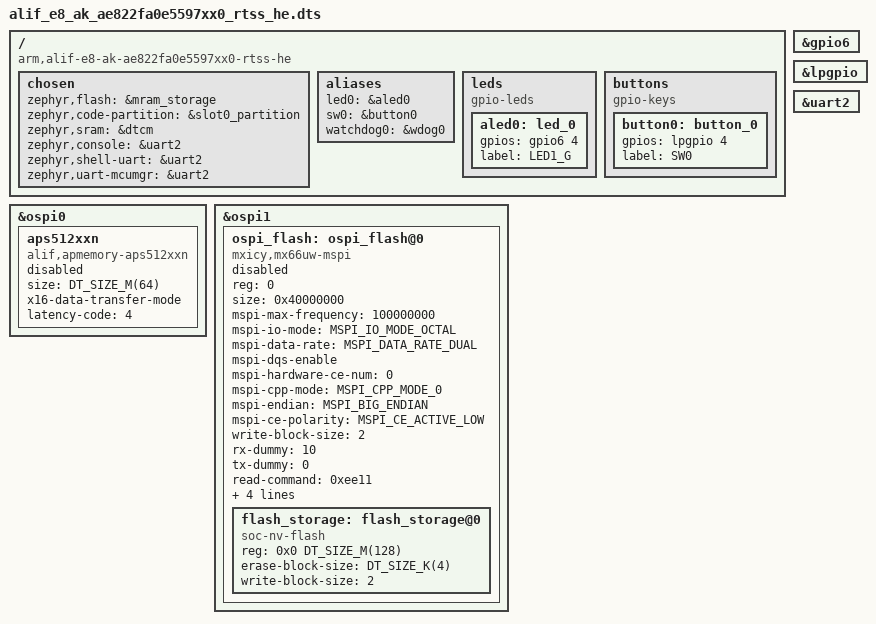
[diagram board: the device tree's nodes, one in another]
/* Copyright (c) 2025 Alif Semiconductor
 *
 * SPDX-License-Identifier: Apache-2.0
 */

/dts-v1/;

#include <alif/ensemble/common/e8_appkit.dtsi>
#include <alif/ensemble/common/ensemble_rtss_he.dtsi>
#include "../common/ensemble-e8-appkit-pinctrl.dtsi"
#include "../common/alif-sd-vsel.dtsi"

/ {
	compatible = "arm,alif-e8-ak-ae822fa0e5597xx0-rtss-he";
	#address-cells = <1>;
	#size-cells = <1>;

	chosen {
		zephyr,flash = &mram_storage;
		zephyr,code-partition = &slot0_partition;
		zephyr,sram = &dtcm;
		zephyr,console = &uart2;
		zephyr,shell-uart = &uart2;
		zephyr,uart-mcumgr = &uart2;
	};

	aliases {
		led0 = &aled0;
		sw0 = &button0;
		watchdog0 = &wdog0;
	};

	leds {
		compatible = "gpio-leds";
		aled0: led_0 {
			gpios = <&gpio6 4 0>;
			label = "LED1_G";
		};
	};
	buttons {
		compatible = "gpio-keys";
		button0: button_0 {
			gpios = <&lpgpio 4 0>;
			label = "SW0";
		};
	};
};

&gpio6 {
	status = "okay";
};

&lpgpio {
	status = "okay";
};

&uart2 {
	status = "okay";
};

&ospi0 {
	aps512xxn: aps512xxn {
		compatible = "alif,apmemory-aps512xxn";
		size = <DT_SIZE_M(64)>;
		x16-data-transfer-mode;
		latency-code = <4>;
		status = "disabled";
	};
};

&ospi1 {
	/* External Flash on MSPI */
	ospi_flash: ospi_flash@0 {
		compatible = "mxicy,mx66uw-mspi";
		reg = <0>;
		size = <0x40000000>;
		mspi-max-frequency = <100000000>;
		mspi-io-mode = "MSPI_IO_MODE_OCTAL";
		mspi-data-rate = "MSPI_DATA_RATE_DUAL";
		mspi-dqs-enable;
		mspi-hardware-ce-num = <0>;
		mspi-cpp-mode = "MSPI_CPP_MODE_0";
		mspi-endian = "MSPI_BIG_ENDIAN";
		mspi-ce-polarity = "MSPI_CE_ACTIVE_LOW";
		write-block-size = <2>;
		rx-dummy = <10>;
		tx-dummy = <0>;
		read-command = <0xee11>;
		write-command = <0x12ed>;
		command-length = "INSTR_2_BYTE";
		address-length = "ADDR_4_BYTE";

		/* Flash Size 128MB */
		#address-cells = <1>;
		#size-cells = <1>;

		flash_storage: flash_storage@0 {
			compatible = "soc-nv-flash";
			reg = <0x0 DT_SIZE_M(128)>;
			erase-block-size = <DT_SIZE_K(4)>;
			write-block-size = <2>;
		};

		/* XiP 128-MB read-only window and disabled. */
		xip-config = <0 0x0 0x08000000 1>;
		status = "disabled";
	};
};
